# SN32F240B register map
Vendor: SONiX Technology Co., Ltd.; Series: SN32F240B; File version: 1.1
CPU: CM0 r0p0, little endian, no MPU, no FPU, 2 interrupt priority bits
Registers are 32-bit, read-write, reset 0x0 unless marked. A register's access mark holds for its fields unless they carry their own. Offsets are from the block's base; [hi:lo] are bit positions; 'fields as' and 'values as' point back to an identical list.

## SN_GPIO3 — General Purpose I/O
Base 0x4004A000
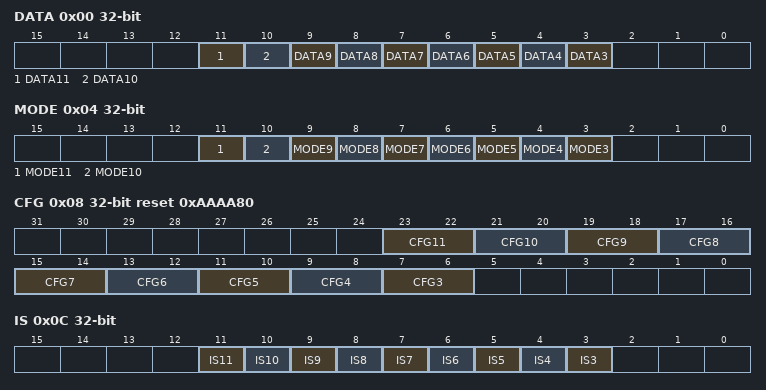
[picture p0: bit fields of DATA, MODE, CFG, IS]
0x00 DATA — Offset:0x00 GPIO Port n Data Register
  [11] DATA11 — Data of Pn.11
    0=Pn.11 is 0; 1=Pn.11 is 1
  [10] DATA10 — Data of Pn.10
    0=Pn.10 is 0; 1=Pn.10 is 1
  [9] DATA9 — Data of Pn.9
    0=Pn.9 is 0; 1=Pn.9 is 1
  [8] DATA8 — Data of Pn.8
    0=Pn.8 is 0; 1=Pn.8 is 1
  [7] DATA7 — Data of Pn.7
    0=Pn.7 is 0; 1=Pn.7 is 1
  [6] DATA6 — Data of Pn.6
    0=Pn.6 is 0; 1=Pn.6 is 1
  [5] DATA5 — Data of Pn.5
    0=Pn.5 is 0; 1=Pn.5 is 1
  [4] DATA4 — Data of Pn.4
    0=Pn.4 is 0; 1=Pn.4 is 1
  [3] DATA3 — Data of Pn.3
    0=Pn.3 is 0; 1=Pn.3 is 1
0x04 MODE — Offset:0x04 GPIO Port n Mode Register
  [11] MODE11 — Mode of Pn.11
    0=I (Pn.11 is Input pin); 1=O (Pn.11 is Output pin)
  [10] MODE10 — Mode of Pn.10
    0=I (Pn.10 is Input pin); 1=O (Pn.10 is Output pin)
  [9] MODE9 — Mode of Pn.9
    0=I (Pn.9 is Input pin); 1=O (Pn.9 is Output pin)
  [8] MODE8 — Mode of Pn.8
    0=I (Pn.8 is Input pin); 1=O (Pn.8 is Output pin)
  [7] MODE7 — Mode of Pn.7
    0=I (Pn.7 is Input pin); 1=O (Pn.7 is Output pin)
  [6] MODE6 — Mode of Pn.6
    0=I (Pn.6 is Input pin); 1=O (Pn.6 is Output pin)
  [5] MODE5 — Mode of Pn.5
    0=I (Pn.5 is Input pin); 1=O (Pn.5 is Output pin)
  [4] MODE4 — Mode of Pn.4
    0=I (Pn.4 is Input pin); 1=O (Pn.4 is Output pin)
  [3] MODE3 — Mode of Pn.3
    0=I (Pn.3 is Input pin); 1=O (Pn.3 is Output pin)
0x08 CFG reset 0xAAAA80 (reset mask 0xFF8) — Offset:0x08 GPIO Port n Configuration Register
  [23:22] CFG11 — Configuration of Pn.11
    0=Enable pull-up resistor; 2=Inactive. (no pull-up resistor enabled, Schmitt trigger enabled); 3=Inactive. (no pull-up resistor enabled, Schmitt trigger disabled, Data register keep low)
  [21:20] CFG10 — Configuration of Pn.10
    values as CFG11
  [19:18] CFG9 — Configuration of Pn.9
    0=Enable pull-up resistor; 2=Inactive. (no pull-up resistor enabled, Schmitt trigger enabled); 3=No pull-up resistor enabled, Schmitt trigger disabled
  [17:16] CFG8 — Configuration of Pn.8
    values as CFG11
  [15:14] CFG7 — Configuration of Pn.7
    values as CFG11
  [13:12] CFG6 — Configuration of Pn.6
    values as CFG11
  [11:10] CFG5 — Configuration of Pn.5
    values as CFG11
  [9:8] CFG4 — Configuration of Pn.4
    values as CFG11
  [7:6] CFG3 — Configuration of Pn.3
    values as CFG11
0x0C IS — Offset:0x0C GPIO Port n Interrupt Sense Register
  [11] IS11 — Interrupt on Pn.11 is event or edge sensitive
    0=Edge (Interrupt on Pn.11 is edge sensitive); 1=Event (Interrupt on Pn.11 is event sensitive)
  [10] IS10 — Interrupt on Pn.10 is event or edge sensitive
    0=Edge (Interrupt on Pn.10 is edge sensitive); 1=Event (Interrupt on Pn.10 is event sensitive)
  [9] IS9 — Interrupt on Pn.9 is event or edge sensitive
    0=Edge (Interrupt on Pn.9 is edge sensitive); 1=Event (Interrupt on Pn.9 is event sensitive)
  [8] IS8 — Interrupt on Pn.8 is event or edge sensitive
    0=Edge (Interrupt on Pn.8 is edge sensitive); 1=Event (Interrupt on Pn.8 is event sensitive)
  [7] IS7 — Interrupt on Pn.7 is event or edge sensitive
    0=Edge (Interrupt on Pn.7 is edge sensitive); 1=Event (Interrupt on Pn.7 is event sensitive)
  [6] IS6 — Interrupt on Pn.6 is event or edge sensitive
    0=Edge (Interrupt on Pn.6 is edge sensitive); 1=Event (Interrupt on Pn.6 is event sensitive)
  [5] IS5 — Interrupt on Pn.5 is event or edge sensitive
    0=Edge (Interrupt on Pn.5 is edge sensitive); 1=Event (Interrupt on Pn.5 is event sensitive)
  [4] IS4 — Interrupt on Pn.4 is event or edge sensitive
    0=Edge (Interrupt on Pn.4 is edge sensitive); 1=Event (Interrupt on Pn.4 is event sensitive)
  [3] IS3 — Interrupt on Pn.3 is event or edge sensitive
    0=Edge (Interrupt on Pn.3 is edge sensitive); 1=Event (Interrupt on Pn.3 is event sensitive)
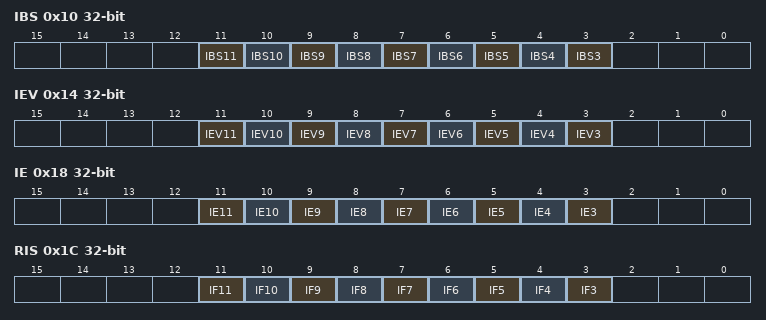
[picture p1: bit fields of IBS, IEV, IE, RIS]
0x10 IBS — Offset:0x10 GPIO Port n Interrupt Both-edge Sense Register
  [11] IBS11 — Interrupt on Pn.11 is triggered ob both edges
    0=IEV (Interrupt on Pn.11 is controlled by GPIOn_IEV register); 1=Both edges on Pn.11 trigger an interrupt
  [10] IBS10 — Interrupt on Pn.10 is triggered ob both edges
    0=IEV (Interrupt on Pn.10 is controlled by GPIOn_IEV register); 1=Both edges on Pn.10 trigger an interrupt
  [9] IBS9 — Interrupt on Pn.9 is triggered ob both edges
    0=IEV (Interrupt on Pn.9 is controlled by GPIOn_IEV register); 1=Both edges on Pn.9 trigger an interrupt
  [8] IBS8 — Interrupt on Pn.8 is triggered ob both edges
    0=IEV (Interrupt on Pn.8 is controlled by GPIOn_IEV register); 1=Both edges on Pn.8 trigger an interrupt
  [7] IBS7 — Interrupt on Pn.7 is triggered ob both edges
    0=IEV (Interrupt on Pn.7 is controlled by GPIOn_IEV register); 1=Both edges on Pn.7 trigger an interrupt
  [6] IBS6 — Interrupt on Pn.6 is triggered ob both edges
    0=IEV (Interrupt on Pn.6 is controlled by GPIOn_IEV register); 1=Both edges on Pn.6 trigger an interrupt
  [5] IBS5 — Interrupt on Pn.5 is triggered ob both edges
    0=IEV (Interrupt on Pn.5 is controlled by GPIOn_IEV register); 1=Both edges on Pn.5 trigger an interrupt
  [4] IBS4 — Interrupt on Pn.4 is triggered ob both edges
    0=IEV (Interrupt on Pn.4 is controlled by GPIOn_IEV register); 1=Both edges on Pn.4 trigger an interrupt
  [3] IBS3 — Interrupt on Pn.3 is triggered ob both edges
    0=IEV (Interrupt on Pn.3 is controlled by GPIOn_IEV register); 1=Both edges on Pn.3 trigger an interrupt
0x14 IEV — Offset:0x14 GPIO Port n Interrupt Event Register
  [11] IEV11 — Interrupt trigged evnet on Pn.11
    0=Rising edge or High level on Pn.11 triggers an interrupt; 1=Falling edge or Low level on Pn.11 triggers an interrupt
  [10] IEV10 — Interrupt trigged evnet on Pn.10
    0=Rising edge or High level on Pn.10 triggers an interrupt; 1=Falling edge or Low level on Pn.10 triggers an interrupt
  [9] IEV9 — Interrupt trigged evnet on Pn.9
    0=Rising edge or High level on Pn.9 triggers an interrupt; 1=Falling edge or Low level on Pn.9 triggers an interrupt
  [8] IEV8 — Interrupt trigged evnet on Pn.8
    0=Rising edge or High level on Pn.8 triggers an interrupt; 1=Falling edge or Low level on Pn.8 triggers an interrupt
  [7] IEV7 — Interrupt trigged evnet on Pn.7
    0=Rising edge or High level on Pn.7 triggers an interrupt; 1=Falling edge or Low level on Pn.7 triggers an interrupt
  [6] IEV6 — Interrupt trigged evnet on Pn.6
    0=Rising edge or High level on Pn.6 triggers an interrupt; 1=Falling edge or Low level on Pn.6 triggers an interrupt
  [5] IEV5 — Interrupt trigged evnet on Pn.5
    0=Rising edge or High level on Pn.5 triggers an interrupt; 1=Falling edge or Low level on Pn.5 triggers an interrupt
  [4] IEV4 — Interrupt trigged evnet on Pn.4
    0=Rising edge or High level on Pn.4 triggers an interrupt; 1=Falling edge or Low level on Pn.4 triggers an interrupt
  [3] IEV3 — Interrupt trigged evnet on Pn.3
    0=Rising edge or High level on Pn.3 triggers an interrupt; 1=Falling edge or Low level on Pn.3 triggers an interrupt
0x18 IE — Offset:0x18 GPIO Port n Interrupt Enable Register
  [11] IE11 — Interrupt on Pn.11 enable
    0=Disable interrupt on Pn.11; 1=Enable interrupt on Pn.11
  [10] IE10 — Interrupt on Pn.10 enable
    0=Disable interrupt on Pn.10; 1=Enable interrupt on Pn.10
  [9] IE9 — Interrupt on Pn.9 enable
    0=Disable interrupt on Pn.9; 1=Enable interrupt on Pn.9
  [8] IE8 — Interrupt on Pn.8 enable
    0=Disable interrupt on Pn.8; 1=Enable interrupt on Pn.8
  [7] IE7 — Interrupt on Pn.7 enable
    0=Disable interrupt on Pn.7; 1=Enable interrupt on Pn.7
  [6] IE6 — Interrupt on Pn.6 enable
    0=Disable interrupt on Pn.6; 1=Enable interrupt on Pn.6
  [5] IE5 — Interrupt on Pn.5 enable
    0=Disable interrupt on Pn.5; 1=Enable interrupt on Pn.5
  [4] IE4 — Interrupt on Pn.4 enable
    0=Disable interrupt on Pn.4; 1=Enable interrupt on Pn.4
  [3] IE3 — Interrupt on Pn.3 enable
    0=Disable interrupt on Pn.3; 1=Enable interrupt on Pn.3
0x1C RIS ro — Offset:0x1C GPIO Port n Raw Interrupt Status Register
  [11] IF11 — Pn.11 raw interrupt flag
    0=No interrupt on Pn.11; 1=Interrupt requirements met on Pn.11
  [10] IF10 — Pn.10 raw interrupt flag
    0=No interrupt on Pn.10; 1=Interrupt requirements met on Pn.10
  [9] IF9 — Pn.9 raw interrupt flag
    0=No interrupt on Pn.9; 1=Interrupt requirements met on Pn.9
  [8] IF8 — Pn.8 raw interrupt flag
    0=No interrupt on Pn.8; 1=Interrupt requirements met on Pn.8
  [7] IF7 — Pn.7 raw interrupt flag
    0=No interrupt on Pn.7; 1=Interrupt requirements met on Pn.7
  [6] IF6 — Pn.6 raw interrupt flag
    0=No interrupt on Pn.6; 1=Interrupt requirements met on Pn.6
  [5] IF5 — Pn.5 raw interrupt flag
    0=No interrupt on Pn.5; 1=Interrupt requirements met on Pn.5
  [4] IF4 — Pn.4 raw interrupt flag
    0=No interrupt on Pn.4; 1=Interrupt requirements met on Pn.4
  [3] IF3 — Pn.3 raw interrupt flag
    0=No interrupt on Pn.3; 1=Interrupt requirements met on Pn.3
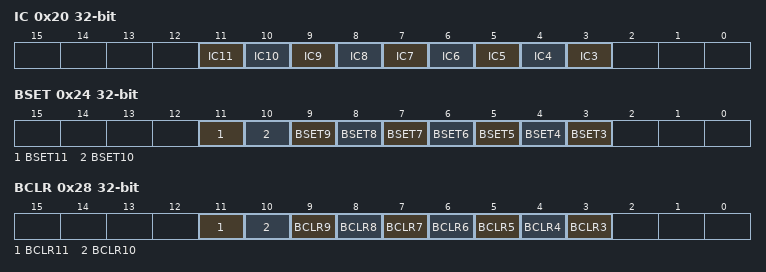
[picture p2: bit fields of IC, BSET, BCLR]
0x20 IC wo — Offset:0x20 GPIO Port n Interrupt Clear Register
  [11] IC11 — Pn.11 interrupt flag clear
    0=No effect; 1=Clear interrupt flag on Pn.11
  [10] IC10 — Pn.10 interrupt flag clear
    0=No effect; 1=Clear interrupt flag on Pn.10
  [9] IC9 — Pn.9 interrupt flag clear
    0=No effect; 1=Clear interrupt flag on Pn.9
  [8] IC8 — Pn.8 interrupt flag clear
    0=No effect; 1=Clear interrupt flag on Pn.8
  [7] IC7 — Pn.7 interrupt flag clear
    0=No effect; 1=Clear interrupt flag on Pn.7
  [6] IC6 — Pn.6 interrupt flag clear
    0=No effect; 1=Clear interrupt flag on Pn.6
  [5] IC5 — Pn.5 interrupt flag clear
    0=No effect; 1=Clear interrupt flag on Pn.5
  [4] IC4 — Pn.4 interrupt flag clear
    0=No effect; 1=Clear interrupt flag on Pn.4
  [3] IC3 — Pn.3 interrupt flag clear
    0=No effect; 1=Clear interrupt flag on Pn.3
0x24 BSET wo — Offset:0x24 GPIO Port n Bits Set Operation Register
  [11] BSET11 — Set Pn.11
    0=No effect; 1=Set (Set Pn.11 to 1)
  [10] BSET10 — Set Pn.10
    0=No effect; 1=Set (Set Pn.10 to 1)
  [9] BSET9 — Set Pn.9
    0=No effect; 1=Set (Set Pn.9 to 1)
  [8] BSET8 — Set Pn.8
    0=No effect; 1=Set (Set Pn.8 to 1)
  [7] BSET7 — Set Pn.7
    0=No effect; 1=Set (Set Pn.7 to 1)
  [6] BSET6 — Set Pn.6
    0=No effect; 1=Set (Set Pn.6 to 1)
  [5] BSET5 — Set Pn.5
    0=No effect; 1=Set (Set Pn.5 to 1)
  [4] BSET4 — Set Pn.4
    0=No effect; 1=Set (Set Pn.4 to 1)
  [3] BSET3 — Set Pn.3
    0=No effect; 1=Set (Set Pn.3 to 1)
0x28 BCLR wo — Offset:0x28 GPIO Port n Bits Clear Operation Register
  [11] BCLR11 — Clear Pn.11
    0=No effect; 1=Clear Pn.11
  [10] BCLR10 — Clear Pn.10
    0=No effect; 1=Clear Pn.10
  [9] BCLR9 — Clear Pn.9
    0=No effect; 1=Clear Pn.9
  [8] BCLR8 — Clear Pn.8
    0=No effect; 1=Clear Pn.8
  [7] BCLR7 — Clear Pn.7
    0=No effect; 1=Clear Pn.7
  [6] BCLR6 — Clear Pn.6
    0=No effect; 1=Clear Pn.6
  [5] BCLR5 — Clear Pn.5
    0=No effect; 1=Clear Pn.5
  [4] BCLR4 — Clear Pn.4
    0=No effect; 1=Clear Pn.4
  [3] BCLR3 — Clear Pn.3
    0=No effect; 1=Clear Pn.3
